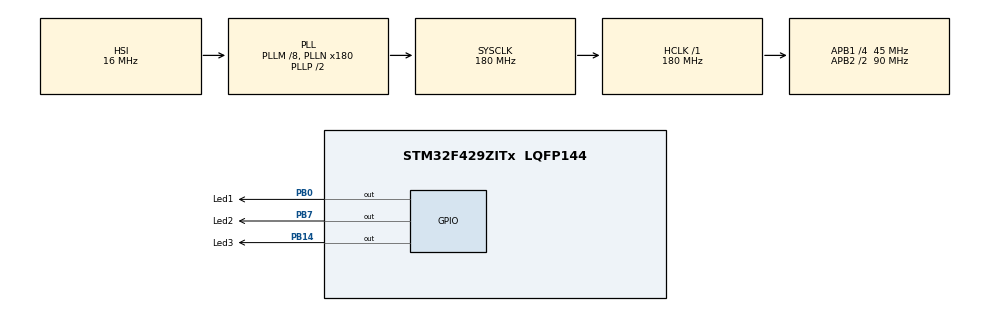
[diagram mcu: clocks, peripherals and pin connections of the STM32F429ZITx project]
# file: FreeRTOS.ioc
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FREERTOS.Queues01=myQueue,16,uint16_t,0,Dynamic,NULL,NULL
FREERTOS.Tasks01=defaultTask,0,128,StartDefaultTask,Default,NULL,Dynamic,NULL,NULL;myTaskLedBlink,-3,128,StartTaskLedBlink,Default,NULL,Dynamic,NULL,NULL;myTaskUartSend,-3,128,StartTaskUartSend,Default,NULL,Dynamic,NULL,NULL
FREERTOS.configUSE_TIMERS=0
Mcu.Family=STM32F4
Mcu.Name=STM32F429ZITx
Mcu.Package=LQFP144
NVIC.PriorityGroup=NVIC_PRIORITYGROUP_4
NVIC.TIM2_IRQn=true\:0\:0\:false\:false\:true\:false\:false
NVIC.TimeBase=TIM2_IRQn
NVIC.TimeBaseIP=TIM2
PB0.GPIO_Label=Led1
PB0.Signal=GPIO_Output
PB14.GPIO_Label=Led3
PB14.Signal=GPIO_Output
PB7.GPIO_Label=Led2
PB7.Signal=GPIO_Output
ProjectManager.HeapSize=0x200
ProjectManager.StackSize=0x400
ProjectManager.TargetToolchain=TrueSTUDIO
RCC.48MHZClocksFreq_Value=90000000
RCC.AHBFreq_Value=180000000
RCC.APB1CLKDivider=RCC_HCLK_DIV4
RCC.APB1Freq_Value=45000000
RCC.APB1TimFreq_Value=90000000
RCC.APB2CLKDivider=RCC_HCLK_DIV2
RCC.APB2Freq_Value=90000000
RCC.APB2TimFreq_Value=180000000
RCC.CortexFreq_Value=180000000
RCC.HCLKFreq_Value=180000000
RCC.HSE_VALUE=25000000
RCC.HSI_VALUE=16000000
RCC.LSE_VALUE=32768
RCC.PLLM=8
RCC.PLLN=180
RCC.SYSCLKFreq_VALUE=180000000
RCC.SYSCLKSource=RCC_SYSCLKSOURCE_PLLCLK
RCC.VCOOutputFreq_Value=360000000
RTC.Date=10
RTC.Hours=0
RTC.Month=RTC_MONTH_FEBRUARY
RTC.Year=18
TIM1.ClockDivision=TIM_CLOCKDIVISION_DIV4
TIM1.Period=20000
TIM1.Prescaler=30000
VP_FREERTOS_VS_ENABLE.Mode=Enabled
VP_RTC_VS_RTC_Activate.Mode=RTC_Enabled
VP_RTC_VS_RTC_Calendar.Mode=RTC_Calendar
VP_SYS_VS_tim2.Mode=TIM2
VP_TIM1_VS_ClockSourceINT.Mode=Internal
board=custom

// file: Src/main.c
/* USER CODE BEGIN Header */
/**
  ******************************************************************************
  * @file           : main.c
  * @brief          : Main program body
  ******************************************************************************
  * This notice applies to any and all portions of this file
  * that are not between comment pairs USER CODE BEGIN and
  * USER CODE END. Other portions of this file, whether
  * inserted by the user or by software development tools
  * are owned by their respective copyright owners.
  *
  * Copyright (c) 2018 STMicroelectronics International N.V.
  * All rights reserved.
  *
  * Redistribution and use in source and binary forms, with or without
  * modification, are permitted, provided that the following conditions are met:
  *
  * 1. Redistribution of source code must retain the above copyright notice,
  *    this list of conditions and the following disclaimer.
  * 2. Redistributions in binary form must reproduce the above copyright notice,
  *    this list of conditions and the following disclaimer in the documentation
  *    and/or other materials provided with the distribution.
  * 3. Neither the name of STMicroelectronics nor the names of other
  *    contributors to this software may be used to endorse or promote products
  *    derived from this software without specific written permission.
  * 4. This software, including modifications and/or derivative works of this
  *    software, must execute solely and exclusively on microcontroller or
  *    microprocessor devices manufactured by or for STMicroelectronics.
  * 5. Redistribution and use of this software other than as permitted under
  *    this license is void and will automatically terminate your rights under
  *    this license.
  *
  * THIS SOFTWARE IS PROVIDED BY STMICROELECTRONICS AND CONTRIBUTORS "AS IS"
  * AND ANY EXPRESS, IMPLIED OR STATUTORY WARRANTIES, INCLUDING, BUT NOT
  * LIMITED TO, THE IMPLIED WARRANTIES OF MERCHANTABILITY, FITNESS FOR A
  * PARTICULAR PURPOSE AND NON-INFRINGEMENT OF THIRD PARTY INTELLECTUAL PROPERTY
  * RIGHTS ARE DISCLAIMED TO THE FULLEST EXTENT PERMITTED BY LAW. IN NO EVENT
  * SHALL STMICROELECTRONICS OR CONTRIBUTORS BE LIABLE FOR ANY DIRECT, INDIRECT,
  * INCIDENTAL, SPECIAL, EXEMPLARY, OR CONSEQUENTIAL DAMAGES (INCLUDING, BUT NOT
  * LIMITED TO, PROCUREMENT OF SUBSTITUTE GOODS OR SERVICES; LOSS OF USE, DATA,
  * OR PROFITS; OR BUSINESS INTERRUPTION) HOWEVER CAUSED AND ON ANY THEORY OF
  * LIABILITY, WHETHER IN CONTRACT, STRICT LIABILITY, OR TORT (INCLUDING
  * NEGLIGENCE OR OTHERWISE) ARISING IN ANY WAY OUT OF THE USE OF THIS SOFTWARE,
  * EVEN IF ADVISED OF THE POSSIBILITY OF SUCH DAMAGE.
  *
  ******************************************************************************
  */
/* USER CODE END Header */

#include "main.h"
#include "cmsis_os.h"
#include "rtc.h"
#include "tim.h"
#include "gpio.h"

void SystemClock_Config(void);
void MX_FREERTOS_Init(void);

int main(void)
{

  /* MCU Configuration--------------------------------------------------------*/

  /* Reset of all peripherals, Initializes the Flash interface and the Systick. */
  HAL_Init();

  /* Configure the system clock */
  SystemClock_Config();

  /* Initialize all configured peripherals */
  MX_GPIO_Init();
  MX_TIM1_Init();
  MX_RTC_Init();
  /* USER CODE BEGIN 2 */
  printf("Start system\n");
  /* USER CODE END 2 */

  /* Call init function for freertos objects (in freertos.c) */
  MX_FREERTOS_Init();

  /* Start scheduler */
  osKernelStart();

  /* We should never get here as control is now taken by the scheduler */

  /* Infinite loop */
  while (1)
  {

  }
}

void SystemClock_Config(void)
{
  RCC_OscInitTypeDef RCC_OscInitStruct = {0};
  RCC_ClkInitTypeDef RCC_ClkInitStruct = {0};
  RCC_PeriphCLKInitTypeDef PeriphClkInitStruct = {0};

  /**Configure the main internal regulator output voltage
  */
  __HAL_RCC_PWR_CLK_ENABLE();
  __HAL_PWR_VOLTAGESCALING_CONFIG(PWR_REGULATOR_VOLTAGE_SCALE1);
  /**Initializes the CPU, AHB and APB busses clocks
  */
  RCC_OscInitStruct.OscillatorType = RCC_OSCILLATORTYPE_HSI|RCC_OSCILLATORTYPE_LSI;
  RCC_OscInitStruct.HSIState = RCC_HSI_ON;
  RCC_OscInitStruct.HSICalibrationValue = RCC_HSICALIBRATION_DEFAULT;
  RCC_OscInitStruct.LSIState = RCC_LSI_ON;
  RCC_OscInitStruct.PLL.PLLState = RCC_PLL_ON;
  RCC_OscInitStruct.PLL.PLLSource = RCC_PLLSOURCE_HSI;
  RCC_OscInitStruct.PLL.PLLM = 8;
  RCC_OscInitStruct.PLL.PLLN = 180;
  RCC_OscInitStruct.PLL.PLLP = RCC_PLLP_DIV2;
  RCC_OscInitStruct.PLL.PLLQ = 4;
  if (HAL_RCC_OscConfig(&RCC_OscInitStruct) != HAL_OK)
  {
    Error_Handler();
  }
  /**Activate the Over-Drive mode
  */
  if (HAL_PWREx_EnableOverDrive() != HAL_OK)
  {
    Error_Handler();
  }
  /**Initializes the CPU, AHB and APB busses clocks
  */
  RCC_ClkInitStruct.ClockType = RCC_CLOCKTYPE_HCLK|RCC_CLOCKTYPE_SYSCLK
                              |RCC_CLOCKTYPE_PCLK1|RCC_CLOCKTYPE_PCLK2;
  RCC_ClkInitStruct.SYSCLKSource = RCC_SYSCLKSOURCE_PLLCLK;
  RCC_ClkInitStruct.AHBCLKDivider = RCC_SYSCLK_DIV1;
  RCC_ClkInitStruct.APB1CLKDivider = RCC_HCLK_DIV4;
  RCC_ClkInitStruct.APB2CLKDivider = RCC_HCLK_DIV2;

  if (HAL_RCC_ClockConfig(&RCC_ClkInitStruct, FLASH_LATENCY_5) != HAL_OK)
  {
    Error_Handler();
  }
  PeriphClkInitStruct.PeriphClockSelection = RCC_PERIPHCLK_RTC;
  PeriphClkInitStruct.RTCClockSelection = RCC_RTCCLKSOURCE_LSI;
  if (HAL_RCCEx_PeriphCLKConfig(&PeriphClkInitStruct) != HAL_OK)
  {
    Error_Handler();
  }
}

void HAL_TIM_PeriodElapsedCallback(TIM_HandleTypeDef *htim)
{
  if (htim->Instance == TIM2) {
    HAL_IncTick();
  }
}

void Error_Handler(void)
{
}

/************************ (C) COPYRIGHT STMicroelectronics *****END OF FILE****/

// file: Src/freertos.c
/* USER CODE BEGIN Header */
/**
  ******************************************************************************
  * File Name          : freertos.c
  * Description        : Code for freertos applications
  ******************************************************************************
  * This notice applies to any and all portions of this file
  * that are not between comment pairs USER CODE BEGIN and
  * USER CODE END. Other portions of this file, whether
  * inserted by the user or by software development tools
  * are owned by their respective copyright owners.
  *
  * Copyright (c) 2018 STMicroelectronics International N.V.
  * All rights reserved.
  *
  * Redistribution and use in source and binary forms, with or without
  * modification, are permitted, provided that the following conditions are met:
  *
  * 1. Redistribution of source code must retain the above copyright notice,
  *    this list of conditions and the following disclaimer.
  * 2. Redistributions in binary form must reproduce the above copyright notice,
  *    this list of conditions and the following disclaimer in the documentation
  *    and/or other materials provided with the distribution.
  * 3. Neither the name of STMicroelectronics nor the names of other
  *    contributors to this software may be used to endorse or promote products
  *    derived from this software without specific written permission.
  * 4. This software, including modifications and/or derivative works of this
  *    software, must execute solely and exclusively on microcontroller or
  *    microprocessor devices manufactured by or for STMicroelectronics.
  * 5. Redistribution and use of this software other than as permitted under
  *    this license is void and will automatically terminate your rights under
  *    this license.
  *
  * THIS SOFTWARE IS PROVIDED BY STMICROELECTRONICS AND CONTRIBUTORS "AS IS"
  * AND ANY EXPRESS, IMPLIED OR STATUTORY WARRANTIES, INCLUDING, BUT NOT
  * LIMITED TO, THE IMPLIED WARRANTIES OF MERCHANTABILITY, FITNESS FOR A
  * PARTICULAR PURPOSE AND NON-INFRINGEMENT OF THIRD PARTY INTELLECTUAL PROPERTY
  * RIGHTS ARE DISCLAIMED TO THE FULLEST EXTENT PERMITTED BY LAW. IN NO EVENT
  * SHALL STMICROELECTRONICS OR CONTRIBUTORS BE LIABLE FOR ANY DIRECT, INDIRECT,
  * INCIDENTAL, SPECIAL, EXEMPLARY, OR CONSEQUENTIAL DAMAGES (INCLUDING, BUT NOT
  * LIMITED TO, PROCUREMENT OF SUBSTITUTE GOODS OR SERVICES; LOSS OF USE, DATA,
  * OR PROFITS; OR BUSINESS INTERRUPTION) HOWEVER CAUSED AND ON ANY THEORY OF
  * LIABILITY, WHETHER IN CONTRACT, STRICT LIABILITY, OR TORT (INCLUDING
  * NEGLIGENCE OR OTHERWISE) ARISING IN ANY WAY OUT OF THE USE OF THIS SOFTWARE,
  * EVEN IF ADVISED OF THE POSSIBILITY OF SUCH DAMAGE.
  *
  ******************************************************************************
  */
/* USER CODE END Header */

#include "FreeRTOS.h"
#include "task.h"
#include "main.h"
#include "cmsis_os.h"

osThreadId defaultTaskHandle;
osThreadId myTaskLedBlinkHandle;
osThreadId myTaskUartSendHandle;
osMessageQId myQueueHandle;

void StartDefaultTask(void const * argument);
void StartTaskLedBlink(void const * argument);
void StartTaskUartSend(void const * argument);

void MX_FREERTOS_Init(void); /* (MISRA C 2004 rule 8.1) */

void MX_FREERTOS_Init(void) {

  /* Create the thread(s) */
  /* definition and creation of defaultTask */
  osThreadDef(defaultTask, StartDefaultTask, osPriorityNormal, 0, 128);
  defaultTaskHandle = osThreadCreate(osThread(defaultTask), NULL);

  /* definition and creation of myTaskLedBlink */
  osThreadDef(myTaskLedBlink, StartTaskLedBlink, osPriorityIdle, 0, 128);
  myTaskLedBlinkHandle = osThreadCreate(osThread(myTaskLedBlink), NULL);

  /* definition and creation of myTaskUartSend */
  osThreadDef(myTaskUartSend, StartTaskUartSend, osPriorityIdle, 0, 128);
  myTaskUartSendHandle = osThreadCreate(osThread(myTaskUartSend), NULL);

  /* Create the queue(s) */
  /* definition and creation of myQueue */
  osMessageQDef(myQueue, 16, uint16_t);
  myQueueHandle = osMessageCreate(osMessageQ(myQueue), NULL);

}

void StartDefaultTask(void const * argument)
{

  /* USER CODE BEGIN StartDefaultTask */
  /* Infinite loop */
  for(;;)
  {
	  printf("Task-2\n");
	HAL_GPIO_TogglePin(Led1_GPIO_Port,Led1_Pin);
    osDelay(100);
  }
  /* USER CODE END StartDefaultTask */
}

void StartTaskLedBlink(void const * argument)
{
  /* USER CODE BEGIN StartTaskLedBlink */
  /* Infinite loop */
  for(;;)
  {
	  printf("Task-1\n");
	HAL_GPIO_TogglePin(Led2_GPIO_Port,Led2_Pin);
    osDelay(250);
  }
  /* USER CODE END StartTaskLedBlink */
}

void StartTaskUartSend(void const * argument)
{
  /* USER CODE BEGIN StartTaskUartSend */
  /* Infinite loop */
  for(;;)
  {
	  printf("Task-3\n");
	HAL_GPIO_TogglePin(Led3_GPIO_Port,Led3_Pin);
    osDelay(300);
  }
  /* USER CODE END StartTaskUartSend */
}

/************************ (C) COPYRIGHT STMicroelectronics *****END OF FILE****/
